# SYSCTL_1.0 register map
Vendor: Texas Instruments
Registers are 32-bit, read-write, no defined reset value unless marked. A register's access mark holds for its fields unless they carry their own. Offsets are as the file gives them; [hi:lo] are bit positions; {n}, {i} and the like mark numbered series; 'fields as' and 'values as' point back to an identical list.

## SYSCTL (part 2 of 2)
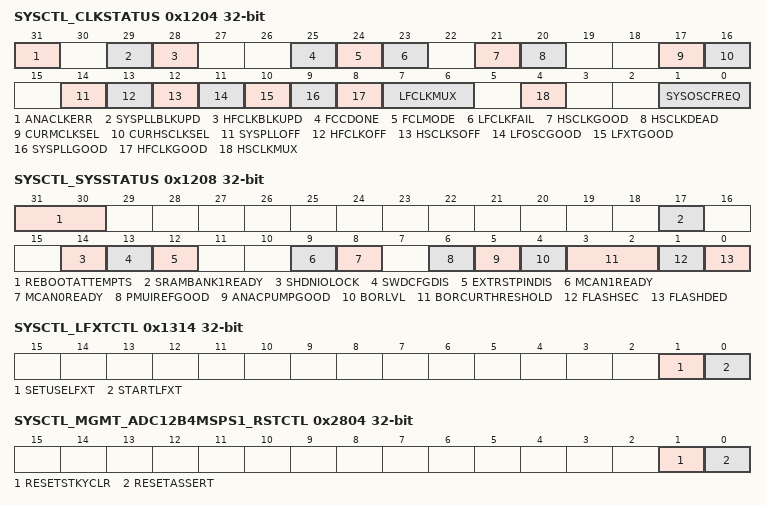
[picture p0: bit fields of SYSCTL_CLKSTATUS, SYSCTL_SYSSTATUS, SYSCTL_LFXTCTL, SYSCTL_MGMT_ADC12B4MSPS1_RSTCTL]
0x1204 SYSCTL_CLKSTATUS ro — Clock module (CKM) status
  [31] ANACLKERR — ANACLKERR is set when the device clock configuration does not support an enabled analog peripheral mode and the analog peripheral may not be functioning as expected.
    0=FALSE (No analog clock errors detected); 1=TRUE (Analog clock error detected)
  [29] SYSPLLBLKUPD — SYSPLLBLKUPD indicates when writes to SYSPLLCFG0/1 and SYSPLLPARAM0/1 are blocked.
    0=FALSE (writes to SYSPLLCFG0/1 and SYSPLLPARAM0/1 are allowed); 1=TRUE (writes to SYSPLLCFG0/1 and SYSPLLPARAM0/1 are blocked)
  [28] HFCLKBLKUPD — HFCLKBLKUPD indicates when writes to the HFCLKCLKCFG register are blocked.
    0=FALSE (Writes to HFCLKCLKCFG are allowed); 1=TRUE (Writes to HFCLKCLKCFG are blocked)
  [25] FCCDONE — FCCDONE indicates when a frequency clock counter capture is complete.
    0=NOTDONE (FCC capture is not done); 1=DONE (FCC capture is done)
  [24] FCLMODE — FCLMODE indicates if the SYSOSC frequency correction loop (FCL) is enabled.
    0=DISABLED (SYSOSC FCL is disabled); 1=ENABLED (SYSOSC FCL is enabled)
  [23] LFCLKFAIL — LFCLKFAIL indicates when the continous LFCLK monitor detects a LFXT or LFCLK_IN clock stuck failure.
    0=FALSE (No LFCLK fault detected); 1=TRUE (LFCLK stuck fault detected)
  [21] HSCLKGOOD — HSCLKGOOD is set by hardware if the selected clock source for HSCLK started successfully.
    0=FALSE (The HSCLK source did not start correctly); 1=TRUE (The HSCLK source started correctly)
  [20] HSCLKDEAD — HSCLKDEAD is set by hardware if the selected source for HSCLK was started but did not start successfully.
    0=FALSE (The HSCLK source was not started or started correctly); 1=TRUE (The HSCLK source did not start correctly)
  [17] CURMCLKSEL — CURMCLKSEL indicates if MCLK is currently sourced from LFCLK.
    0=NOTLFCLK (MCLK is not sourced from LFCLK); 1=LFCLK (MCLK is sourced from LFCLK)
  [16] CURHSCLKSEL — CURHSCLKSEL indicates the current clock source for HSCLK.
    0=SYSPLL (HSCLK is currently sourced from the SYSPLL); 1=HFCLK (HSCLK is currently sourced from the HFCLK)
  [14] SYSPLLOFF — SYSPLLOFF indicates if the SYSPLL is disabled or was dead at startup. When the SYSPLL is started, SYSPLLOFF is cleared by hardware. Following startup of the SYSPLL, if the SYSPLL startup monitor determines that the SYSPLL was not started correctly, SYSPLLOFF is set.
    0=FALSE (SYSPLL started correctly and is enabled); 1=TRUE (SYSPLL is disabled or was dead startup)
  [13] HFCLKOFF — HFCLKOFF indicates if the HFCLK is disabled or was dead at startup. When the HFCLK is started, HFCLKOFF is cleared by hardware. Following startup of the HFCLK, if the HFCLK startup monitor determines that the HFCLK was not started correctly, HFCLKOFF is set.
    0=FALSE (HFCLK started correctly and is enabled); 1=TRUE (HFCLK is disabled or was dead at startup)
  [12] HSCLKSOFF — HSCLKSOFF is set when the high speed clock sources (SYSPLL, HFCLK) are disabled or dead. It is the logical AND of HFCLKOFF and SYSPLLOFF.
    0=FALSE (SYSPLL, HFCLK, or both were started correctly and remain enabled); 1=TRUE (SYSPLL and HFCLK are both either off or dead)
  [11] LFOSCGOOD — LFOSCGOOD indicates when the LFOSC startup has completed and the LFOSC is ready for use.
    0=FALSE (LFOSC is not ready); 1=TRUE (LFOSC is ready)
  [10] LFXTGOOD — LFXTGOOD indicates if the LFXT started correctly. When the LFXT is started, LFXTGOOD is cleared by hardware. After the startup settling time has expired, the LFXT status is tested. If the LFXT started successfully the LFXTGOOD bit is set, else it is left cleared.
    0=FALSE (LFXT did not start correctly); 1=TRUE (LFXT started correctly)
  [9] SYSPLLGOOD — SYSPLLGOOD indicates if the SYSPLL started correctly. When the SYSPLL is started, SYSPLLGOOD is cleared by hardware. After the startup settling time has expired, the SYSPLL status is tested. If the SYSPLL started successfully the SYSPLLGOOD bit is set, else it is left cleared.
    0=FALSE (SYSPLL did not start correctly); 1=TRUE (SYSPLL started correctly)
  [8] HFCLKGOOD — HFCLKGOOD indicates that the HFCLK started correctly. When the HFXT is started or HFCLK_IN is selected as the HFCLK source, this bit will be set by hardware if a valid HFCLK is detected, and cleared if HFCLK is not operating within the expected range.
    0=FALSE (HFCLK did not start correctly); 1=TRUE (HFCLK started correctly)
  [7:6] LFCLKMUX — LFCLKMUX indicates if LFCLK is sourced from the internal LFOSC, the low frequency crystal (LFXT), or the LFCLK_IN digital clock input.
    0=LFOSC (LFCLK is sourced from the internal LFOSC); 1=LFXT (LFCLK is sourced from the LFXT (crystal)); 2=EXLF (LFCLK is sourced from LFCLK_IN (external digital clock input))
  [4] HSCLKMUX — HSCLKMUX indicates if MCLK is currently sourced from the high-speed clock (HSCLK).
    0=SYSOSC (MCLK is not sourced from HSCLK); 1=HSCLK (MCLK is sourced from HSCLK)
  [1:0] SYSOSCFREQ — SYSOSCFREQ indicates the current SYSOSC operating frequency.
    0=SYSOSC32M (SYSOSC is at base frequency (32MHz)); 1=SYSOSC4M (SYSOSC is at low frequency (4MHz)); 2=SYSOSCUSER (SYSOSC is at the user-trimmed frequency (16 or 24MHz)); 3=SYSOSCTURBO (Reserved)
0x1208 SYSCTL_SYSSTATUS ro — System status information
  [31:30] REBOOTATTEMPTS — REBOOTATTEMPTS indicates the number of boot attempts taken before the user application starts.
  [17] SRAMBANK1READY — SRAM BANK1 READY STATE
    0=FALSE (SRAM BANK1 is NOT READY for access); 1=TRUE (SRAM BANK1 is READY for access)
  [14] SHDNIOLOCK — SHDNIOLOCK indicates when IO is locked due to SHUTDOWN
    0=FALSE (IO IS NOT Locked due to SHUTDOWN); 1=TRUE (IO IS Locked due to SHUTDOWN)
  [13] SWDCFGDIS — SWDCFGDIS indicates when user has disabled the use of SWD Port
    0=FALSE (SWD Port Enabled); 1=TRUE (SWD Port Disabled)
  [12] EXTRSTPINDIS — EXTRSTPINDIS indicates when user has disabled the use of external reset pin
    0=FALSE (External Reset Pin Enabled); 1=TRUE (External Reset Pin Disabled)
  [9] MCAN1READY — MCAN1READY indicates when the MCAN1 peripheral is ready.
    0=FALSE (MCAN1 is not ready); 1=TRUE (MCAN1 is ready)
  [8] MCAN0READY — MCAN0READY indicates when the MCAN0 peripheral is ready.
    0=FALSE (MCAN0 is not ready); 1=TRUE (MCAN0 is ready)
  [6] PMUIREFGOOD — PMUIREFGOOD is set by hardware when the PMU current reference is ready.
    0=FALSE (IREF is not ready); 1=TRUE (IREF is ready)
  [5] ANACPUMPGOOD — ANACPUMPGOOD is set by hardware when the VBOOST analog mux charge pump is ready.
    0=FALSE (VBOOST is not ready); 1=TRUE (VBOOST is ready)
  [4] BORLVL — BORLVL indicates if a BOR event occured and the BOR threshold was switched to BOR0 by hardware.
    0=FALSE (No BOR violation occured); 1=TRUE (A BOR violation occured and the BOR threshold was switched to BOR0)
  [3:2] BORCURTHRESHOLD — BORCURTHRESHOLD indicates the active brown-out reset supply monitor configuration.
    0=BORMIN (Default minimum threshold; a BOR0- violation triggers a BOR); 1=BORLEVEL1 (A BOR1- violation generates a BORLVL interrupt); 2=BORLEVEL2 (A BOR2- violation generates a BORLVL interrupt); 3=BORLEVEL3 (A BOR3- violation generates a BORLVL interrupt)
  [1] FLASHSEC — FLASHSEC indicates if a flash ECC single bit error was detected and corrected (SEC).
    0=FALSE (No flash ECC single bit error detected); 1=TRUE (Flash ECC single bit error was detected and corrected)
  [0] FLASHDED — FLASHDED indicates if a flash ECC double bit error was detected (DED).
    0=FALSE (No flash ECC double bit error detected); 1=TRUE (Flash ECC double bit error detected)
0x120C SYSCTL_DEDERRADDR access not given — Memory DED Address
0x1220 SYSCTL_RSTCAUSE ro — Reset cause
  [4:0] ID — ID is a read-to-clear field which indicates the lowest level reset cause since the last read.
    0=NORST (No reset since last read); 1=PORHWFAIL (POR- violation, SHUTDNSTOREx or PMU trim parity fault); 2=POREXNRST (NRST triggered POR (>1s hold)); 3=PORSW (Software triggered POR); 4=BORSUPPLY (BOR0- violation); 5=BORWAKESHUTDN (SHUTDOWN mode exit); 8=BOOTNONPMUPARITY (Non-PMU trim parity fault); 9=BOOTCLKFAIL (Fatal clock failure); 12=BOOTEXNRST (NRST triggered BOOTRST (<1s hold)); 13=BOOTSW (Software triggered BOOTRST); 14=BOOTWWDT0 (WWDT0 violation); 16=SYSBSLEXIT (BSL exit); 17=SYSBSLENTRY (BSL entry); 19=SYSWWDT1 (WWDT1 violation); 20=SYSFLASHECC (Flash uncorrectable ECC error); 21=SYSCPULOCK (CPULOCK violation); 26=SYSDBG (Debug triggered SYSRST); 27=SYSSW (Software triggered SYSRST); 28=CPUDBG (Debug triggered CPURST); 29=CPUSW (Software triggered CPURST)
0x1300 SYSCTL_RESETLEVEL — Reset level for application-triggered reset command
  [2:0] LEVEL — LEVEL is used to specify the type of reset to be issued when RESETCMD is set to generate a software triggered reset.
    0=CPU (Issue a SYSRST (CPU plus peripherals only)); 1=BOOT (Issue a BOOTRST (CPU, peripherals, and boot configuration routine)); 2=BOOTLOADERENTRY (Issue a SYSRST and enter the boot strap loader (BSL)); 3=POR (Issue a power-on reset (POR)); 4=BOOTLOADEREXIT (Issue a SYSRST and exit the boot strap loader (BSL))
0x1304 SYSCTL_RESETCMD — Execute an application-triggered reset command
  [0] GO — Execute the reset specified in RESETLEVEL.LEVEL. Must be written together with the KEY.
    1=TRUE (Issue reset)
0x1308 SYSCTL_BORTHRESHOLD — BOR threshold selection
  [1:0] LEVEL — LEVEL specifies the desired BOR threshold and BOR mode.
    values as SYSCTL_SYSSTATUS.BORCURTHRESHOLD
0x130C SYSCTL_BORCLRCMD — Set the BOR threshold
  [0] GO — GO clears any prior BOR violation status indications and attempts to change the active BOR mode to that specified in the LEVEL field of the BORTHRESHOLD register.
    1=TRUE (Issue clear)
0x1310 SYSCTL_SYSOSCFCLCTL — SYSOSC frequency correction loop (FCL) ROSC enable
  [0] SETUSEFCL — Set SETUSEFCL to enable the frequency correction loop in SYSOSC. Once enabled, this state is locked until the next BOOTRST.
    1=TRUE (Enable the SYSOSC FCL)
0x1314 SYSCTL_LFXTCTL — LFXT and LFCLK control
  [1] SETUSELFXT — Set SETUSELFXT to switch LFCLK to LFXT. Once set, SETUSELFXT remains set until the next BOOTRST.
    0=FALSE; 1=TRUE (Use LFXT as the LFCLK source)
  [0] STARTLFXT — Set STARTLFXT to start the low frequency crystal oscillator (LFXT). Once set, STARTLFXT remains set until the next BOOTRST.
    0=FALSE (LFXT not started); 1=TRUE (Start LFXT)
0x1318 SYSCTL_EXLFCTL — LFCLK_IN and LFCLK control
  [0] SETUSEEXLF — Set SETUSEEXLF to switch LFCLK to the LFCLK_IN digital clock input. Once set, SETUSEEXLF remains set until the next BOOTRST.
    1=TRUE (Use LFCLK_IN as the LFCLK source)
0x131C SYSCTL_SHDNIOREL — SHUTDOWN IO release control
  [0] RELEASE — Set RELEASE to release the IO after a SHUTDOWN mode exit.
    1=TRUE (Release IO)
0x1320 SYSCTL_EXRSTPIN — Disable the reset function of the NRST pin
  [0] DISABLE — Set DISABLE to disable the reset function of the NRST pin. Once set, this configuration is locked until the next POR.
    0=FALSE (Reset function of NRST pin is enabled); 1=TRUE (Reset function of NRST pin is disabled)
0x1324 SYSCTL_SYSSTATUSCLR — Clear sticky bits of SYSSTATUS
  [0] ALLECC — Set ALLECC to clear all ECC related SYSSTATUS indicators.
    1=CLEAR (Clear ECC error state)
0x1328 SYSCTL_SWDCFG — Disable the SWD function on the SWD pins
  [0] DISABLE — Set DISABLE to disable the SWD function on SWD pins, allowing the SWD pins to be used as GPIO.
    1=TRUE (Disable SWD function on SWD pins)
0x132C SYSCTL_FCCCMD — Frequency clock counter start capture
  [0] GO — Set GO to start a capture with the frequency clock counter (FCC).
    1=TRUE
{0x1400+4i} SYSCTL_SHUTDNSTORE{i} (i=0..3) — Shutdown storage memory (byte {i})
  [7:0] DATA — Shutdown storage byte {i}
0x2800 SYSCTL_MGMT_ADC12B4MSPS1_PWREN — IP Enable Register
  [0] ENABLE — IP Enable
    0=Disable; 1=Enable
0x2804 SYSCTL_MGMT_ADC12B4MSPS1_RSTCTL — Power Control Register - Write Only Register, Always Read as 0
  [1] RESETSTKYCLR — Clear the RESET STICKY Bit
    1=Clear
  [0] RESETASSERT — Assert Reset to IP Domain.
    1=Do
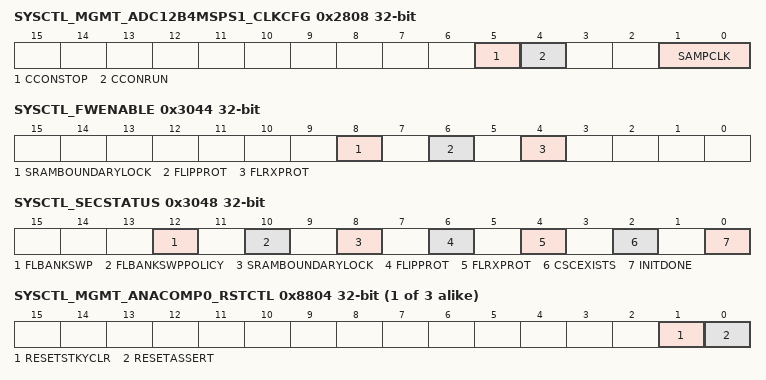
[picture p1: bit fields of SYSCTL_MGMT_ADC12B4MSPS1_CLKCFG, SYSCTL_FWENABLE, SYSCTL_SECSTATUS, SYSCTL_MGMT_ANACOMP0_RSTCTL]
0x2808 SYSCTL_MGMT_ADC12B4MSPS1_CLKCFG — IP Clock Configuration Register
  [5] CCONSTOP — Conversion Clock is ON during STOP Mode
    0=Disable; 1=Enable
  [4] CCONRUN — Conversion Clock is ON during RUN Mode
    0=Disable; 1=Enable
  [1:0] SAMPCLK — Sample Window Clock
    0=ULPCLK; 1=SYSOSC; 2=HFCLK
0x2814 SYSCTL_MGMT_ADC12B4MSPS1_STAT ro — IP State Register - Read Only
  [16] RESETSTKY — IP has been Reset
    0=clear; 1=Set
0x3000 SYSCTL_FWEPROTMAIN access not given — 1 Sector Write-Erase per bit starting at address 0x0 of flash
0x3014 SYSCTL_FWPROTMAINDATA — Read-Write Protection for first 4 Sectors of Data Bank
  [7:0] DATA — 00: Both RW allowed 01: Read Only 10: No Read No Write 11: No Read No Write - Not Used
0x3018 SYSCTL_FRXPROTMAINSTART — Flash RX Protection Start Address
  [21:6] ADDR — Flash RX Protection Start Address 64B granularity
0x301C SYSCTL_FRXPROTMAINEND — Flash RX Protection End Address
  [21:6] ADDR — Flash RX Protection End Address 64B granularity
0x3020 SYSCTL_FIPPROTMAINSTART — Flash IP Protection Start Address
  [21:6] ADDR — Flash IP Protection Start Address 64B granularity
0x3024 SYSCTL_FIPPROTMAINEND — Flash IP Protection End Address
  [21:6] ADDR — Flash IP Protection End Address 64B granularity
0x3038 SYSCTL_FLBANKSWPPOLICY — Flash Bank Swap Policy
  [0] DISABLE — 1: Disables Policy To Allow Flash Bank Swapping
    1=TRUE (Disallow Bank Swap)
0x303C SYSCTL_FLBANKSWP — Flash MAIN bank address swap
  [0] USEUPPER — 1: Use Upper Bank as Logical 0
    0=DISABLE (Normal (default) memory map addressing scheme); 1=ENABLE (Flash upper region address space swapped with lower region)
0x3044 SYSCTL_FWENABLE — Security Firewall Enable Register
  [8] SRAMBOUNDARYLOCK — 1: Blocks Writes from Changing SRAMBOUNDARY MMR
    1=ENABLE (SRAMBOUNDARY MMR Locked)
  [6] FLIPPROT — 1: Flash Read IP ProtectionActive
    1=ENABLE (Turn On Flash IP Protection)
  [4] FLRXPROT — 1: Flash Read Execute Protection Active
    1=ENABLE (Turn On Flash Read-eXecute Protection)
0x3048 SYSCTL_SECSTATUS ro — Security Configuration status
  [12] FLBANKSWP — 1: Upper and Lower Banks have been swapped
  [10] FLBANKSWPPOLICY — 1: Upper and Lower Banks allowed to be swapped
    0=DISABLED; 1=ENABLED
  [8] SRAMBOUNDARYLOCK — 1: SRAM Boundary MMR Locked
    0=DISABLED; 1=ENABLED
  [6] FLIPPROT — 1: Flash IP Protection Active
    0=DISABLED; 1=ENABLED
  [4] FLRXPROT — 1: Flash Read Execute Protection Active
    0=DISABLED; 1=ENABLED
  [2] CSCEXISTS — 1: CSC Exists in the system
    0=NO (System does not have a CSC); 1=YES (System does have a CSC)
  [0] INITDONE — 1: CSC has been completed
    0=NO (INIT is not yet done); 1=YES (INIT is done)
0x3060 SYSCTL_INITDONE — INITCODE PASS
  [0] PASS — INITCODE writes 1 for PASS, left unwritten a timeout will occur if not blocked
    1=TRUE (INITCODE PASS)
{0x8800+0x2000*i} SYSCTL_MGMT_ANACOMP{i}_PWREN (i=0..2) — IP Enable Register
  [0] ENABLE — IP Enable
    0=Disable; 1=Enable
{0x8804+0x2000*i} SYSCTL_MGMT_ANACOMP{i}_RSTCTL (i=0..2) — Power Control Register - Write Only Register, Always Read as 0
  fields as SYSCTL_MGMT_ADC12B4MSPS1_RSTCTL
{0x8808+0x2000*i} SYSCTL_MGMT_ANACOMP{i}_CLKCFG (i=0..2) — IP Clock Configuration Register
  [8] BLOCKASYNC — Async Clock Request is blocked from starting SYSOSC or forcing bus clock to 32MHz
    0=Disable; 1=Enable
{0x8814+0x2000*i} SYSCTL_MGMT_ANACOMP{i}_STAT ro (i=0..2) — IP State Register - Read Only
  [16] RESETSTKY — IP has been Reset
    0=clear; 1=Set
0x18800 SYSCTL_MGMT_DAC12B0_PWREN — IP Enable Register
  [0] ENABLE — IP Enable
    0=Disable; 1=Enable
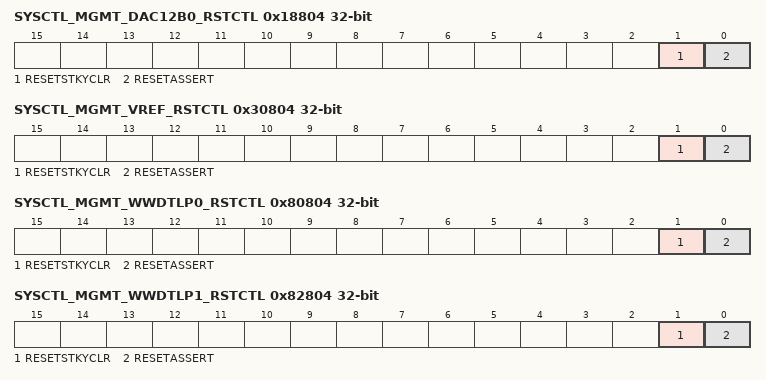
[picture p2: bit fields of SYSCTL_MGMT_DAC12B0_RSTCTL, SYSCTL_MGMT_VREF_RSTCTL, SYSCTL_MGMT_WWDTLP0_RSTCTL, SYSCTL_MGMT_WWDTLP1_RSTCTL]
0x18804 SYSCTL_MGMT_DAC12B0_RSTCTL — Power Control Register - Write Only Register, Always Read as 0
  fields as SYSCTL_MGMT_ADC12B4MSPS1_RSTCTL
0x18814 SYSCTL_MGMT_DAC12B0_STAT ro — IP State Register - Read Only
  [16] RESETSTKY — IP has been Reset
    0=clear; 1=Set
0x30800 SYSCTL_MGMT_VREF_PWREN — IP Enable Register
  [0] ENABLE — IP Enable
    0=Disable; 1=Enable
0x30804 SYSCTL_MGMT_VREF_RSTCTL — Power Control Register - Write Only Register, Always Read as 0
  fields as SYSCTL_MGMT_ADC12B4MSPS1_RSTCTL
0x30814 SYSCTL_MGMT_VREF_STAT ro — IP State Register - Read Only
  [16] RESETSTKY — IP has been Reset
    0=clear; 1=Set
0x80800 SYSCTL_MGMT_WWDTLP0_PWREN — IP Enable Register
  [0] ENABLE — IP Enable
    0=Disable; 1=Enable
0x80804 SYSCTL_MGMT_WWDTLP0_RSTCTL — Power Control Register - Write Only Register, Always Read as 0
  fields as SYSCTL_MGMT_ADC12B4MSPS1_RSTCTL
0x80814 SYSCTL_MGMT_WWDTLP0_STAT ro — IP State Register - Read Only
  [16] RESETSTKY — IP has been Reset
    0=clear; 1=Set
0x82800 SYSCTL_MGMT_WWDTLP1_PWREN — IP Enable Register
  [0] ENABLE — IP Enable
    0=Disable; 1=Enable
0x82804 SYSCTL_MGMT_WWDTLP1_RSTCTL — Power Control Register - Write Only Register, Always Read as 0
  fields as SYSCTL_MGMT_ADC12B4MSPS1_RSTCTL
0x82814 SYSCTL_MGMT_WWDTLP1_STAT ro — IP State Register - Read Only
  [16] RESETSTKY — IP has been Reset
    0=clear; 1=Set
0x84800 SYSCTL_MGMT_GPTIMER16B2CCLP0_PWREN — IP Enable Register
  [0] ENABLE — IP Enable
    0=Disable; 1=Enable
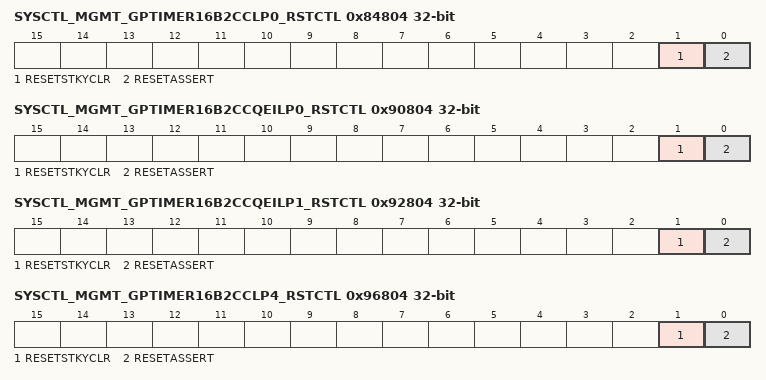
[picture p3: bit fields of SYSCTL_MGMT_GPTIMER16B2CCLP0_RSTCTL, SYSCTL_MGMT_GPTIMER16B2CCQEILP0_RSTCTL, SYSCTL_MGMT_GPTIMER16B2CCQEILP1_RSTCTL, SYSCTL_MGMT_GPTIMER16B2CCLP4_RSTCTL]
0x84804 SYSCTL_MGMT_GPTIMER16B2CCLP0_RSTCTL — Power Control Register - Write Only Register, Always Read as 0
  fields as SYSCTL_MGMT_ADC12B4MSPS1_RSTCTL
0x84814 SYSCTL_MGMT_GPTIMER16B2CCLP0_STAT ro — IP State Register - Read Only
  [16] RESETSTKY — IP has been Reset
    0=clear; 1=Set
0x90800 SYSCTL_MGMT_GPTIMER16B2CCQEILP0_PWREN — IP Enable Register
  [0] ENABLE — IP Enable
    0=Disable; 1=Enable
0x90804 SYSCTL_MGMT_GPTIMER16B2CCQEILP0_RSTCTL — Power Control Register - Write Only Register, Always Read as 0
  fields as SYSCTL_MGMT_ADC12B4MSPS1_RSTCTL
0x90814 SYSCTL_MGMT_GPTIMER16B2CCQEILP0_STAT ro — IP State Register - Read Only
  [16] RESETSTKY — IP has been Reset
    0=clear; 1=Set
0x92800 SYSCTL_MGMT_GPTIMER16B2CCQEILP1_PWREN — IP Enable Register
  [0] ENABLE — IP Enable
    0=Disable; 1=Enable
0x92804 SYSCTL_MGMT_GPTIMER16B2CCQEILP1_RSTCTL — Power Control Register - Write Only Register, Always Read as 0
  fields as SYSCTL_MGMT_ADC12B4MSPS1_RSTCTL
0x92814 SYSCTL_MGMT_GPTIMER16B2CCQEILP1_STAT ro — IP State Register - Read Only
  [16] RESETSTKY — IP has been Reset
    0=clear; 1=Set
0x94808 SYSCTL_MGMT_RTC_CLKCFG — IP Clock Configuration Register
  fields as SYSCTL_MGMT_ANACOMP0_CLKCFG
0x96800 SYSCTL_MGMT_GPTIMER16B2CCLP4_PWREN — IP Enable Register
  [0] ENABLE — IP Enable
    0=Disable; 1=Enable
0x96804 SYSCTL_MGMT_GPTIMER16B2CCLP4_RSTCTL — Power Control Register - Write Only Register, Always Read as 0
  fields as SYSCTL_MGMT_ADC12B4MSPS1_RSTCTL
0x96814 SYSCTL_MGMT_GPTIMER16B2CCLP4_STAT ro — IP State Register - Read Only
  [16] RESETSTKY — IP has been Reset
    0=clear; 1=Set
{0xA0800+0x2000*i} SYSCTL_MGMT_GPIO{i}_PWREN (i=0..2) — IP Enable Register
  [0] ENABLE — IP Enable
    0=Disable; 1=Enable
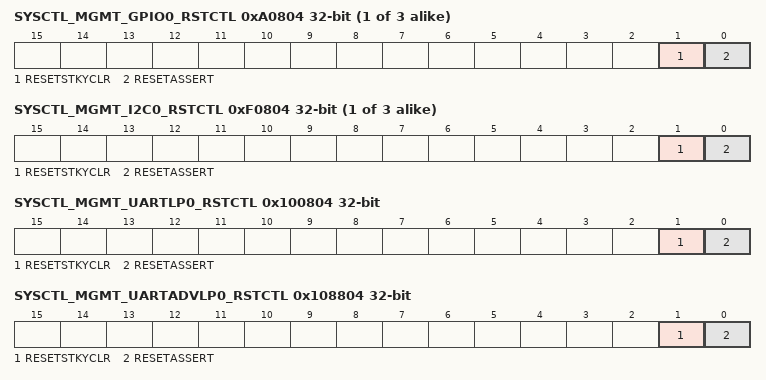
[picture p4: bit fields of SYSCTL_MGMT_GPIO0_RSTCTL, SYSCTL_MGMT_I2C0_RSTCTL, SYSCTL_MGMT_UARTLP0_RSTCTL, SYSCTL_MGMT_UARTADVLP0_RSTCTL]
{0xA0804+0x2000*i} SYSCTL_MGMT_GPIO{i}_RSTCTL (i=0..2) — Power Control Register - Write Only Register, Always Read as 0
  fields as SYSCTL_MGMT_ADC12B4MSPS1_RSTCTL
{0xA0814+0x2000*i} SYSCTL_MGMT_GPIO{i}_STAT ro (i=0..2) — IP State Register - Read Only
  [16] RESETSTKY — IP has been Reset
    0=clear; 1=Set
{0xF0800+0x2000*i} SYSCTL_MGMT_I2C{i}_PWREN (i=0..2) — IP Enable Register
  [0] ENABLE — IP Enable
    0=Disable; 1=Enable
{0xF0804+0x2000*i} SYSCTL_MGMT_I2C{i}_RSTCTL (i=0..2) — Power Control Register - Write Only Register, Always Read as 0
  fields as SYSCTL_MGMT_ADC12B4MSPS1_RSTCTL
{0xF0808+0x2000*i} SYSCTL_MGMT_I2C{i}_CLKCFG (i=0..2) — IP Clock Configuration Register
  fields as SYSCTL_MGMT_ANACOMP0_CLKCFG
{0xF0814+0x2000*i} SYSCTL_MGMT_I2C{i}_STAT ro (i=0..2) — IP State Register - Read Only
  [16] RESETSTKY — IP has been Reset
    0=clear; 1=Set
0x100800 SYSCTL_MGMT_UARTLP0_PWREN — IP Enable Register
  [0] ENABLE — IP Enable
    0=Disable; 1=Enable
0x100804 SYSCTL_MGMT_UARTLP0_RSTCTL — Power Control Register - Write Only Register, Always Read as 0
  fields as SYSCTL_MGMT_ADC12B4MSPS1_RSTCTL
0x100808 SYSCTL_MGMT_UARTLP0_CLKCFG — IP Clock Configuration Register
  fields as SYSCTL_MGMT_ANACOMP0_CLKCFG
0x100814 SYSCTL_MGMT_UARTLP0_STAT ro — IP State Register - Read Only
  [16] RESETSTKY — IP has been Reset
    0=clear; 1=Set
0x108800 SYSCTL_MGMT_UARTADVLP0_PWREN — IP Enable Register
  [0] ENABLE — IP Enable
    0=Disable; 1=Enable
0x108804 SYSCTL_MGMT_UARTADVLP0_RSTCTL — Power Control Register - Write Only Register, Always Read as 0
  fields as SYSCTL_MGMT_ADC12B4MSPS1_RSTCTL
0x108808 SYSCTL_MGMT_UARTADVLP0_CLKCFG — IP Clock Configuration Register
  fields as SYSCTL_MGMT_ANACOMP0_CLKCFG
0x108814 SYSCTL_MGMT_UARTADVLP0_STAT ro — IP State Register - Read Only
  [16] RESETSTKY — IP has been Reset
    0=clear; 1=Set
0x10A800 SYSCTL_MGMT_UARTADVLP1_PWREN — IP Enable Register
  [0] ENABLE — IP Enable
    0=Disable; 1=Enable
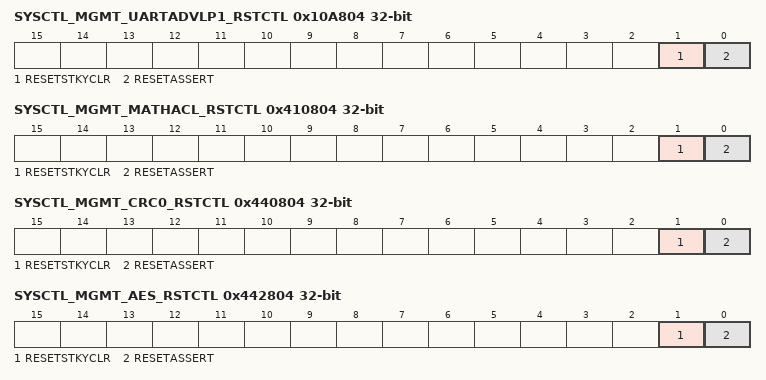
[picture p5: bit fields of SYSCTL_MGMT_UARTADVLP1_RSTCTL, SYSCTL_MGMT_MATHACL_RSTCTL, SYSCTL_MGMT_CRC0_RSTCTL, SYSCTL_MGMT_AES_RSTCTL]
0x10A804 SYSCTL_MGMT_UARTADVLP1_RSTCTL — Power Control Register - Write Only Register, Always Read as 0
  fields as SYSCTL_MGMT_ADC12B4MSPS1_RSTCTL
0x10A808 SYSCTL_MGMT_UARTADVLP1_CLKCFG — IP Clock Configuration Register
  fields as SYSCTL_MGMT_ANACOMP0_CLKCFG
0x10A814 SYSCTL_MGMT_UARTADVLP1_STAT ro — IP State Register - Read Only
  [16] RESETSTKY — IP has been Reset
    0=clear; 1=Set
0x410800 SYSCTL_MGMT_MATHACL_PWREN — IP Enable Register
  [0] ENABLE — IP Enable
    0=Disable; 1=Enable
0x410804 SYSCTL_MGMT_MATHACL_RSTCTL — Power Control Register - Write Only Register, Always Read as 0
  fields as SYSCTL_MGMT_ADC12B4MSPS1_RSTCTL
0x410814 SYSCTL_MGMT_MATHACL_STAT ro — IP State Register - Read Only
  [16] RESETSTKY — IP has been Reset
    0=clear; 1=Set
0x440800 SYSCTL_MGMT_CRC0_PWREN — IP Enable Register
  [0] ENABLE — IP Enable
    0=Disable; 1=Enable
0x440804 SYSCTL_MGMT_CRC0_RSTCTL — Power Control Register - Write Only Register, Always Read as 0
  fields as SYSCTL_MGMT_ADC12B4MSPS1_RSTCTL
0x440814 SYSCTL_MGMT_CRC0_STAT ro — IP State Register - Read Only
  [16] RESETSTKY — IP has been Reset
    0=clear; 1=Set
0x442800 SYSCTL_MGMT_AES_PWREN — IP Enable Register
  [0] ENABLE — IP Enable
    0=Disable; 1=Enable
0x442804 SYSCTL_MGMT_AES_RSTCTL — Power Control Register - Write Only Register, Always Read as 0
  fields as SYSCTL_MGMT_ADC12B4MSPS1_RSTCTL
0x442814 SYSCTL_MGMT_AES_STAT ro — IP State Register - Read Only
  [16] RESETSTKY — IP has been Reset
    0=clear; 1=Set
0x444800 SYSCTL_MGMT_TRNG_PWREN — IP Enable Register
  [0] ENABLE — IP Enable
    0=Disable; 1=Enable
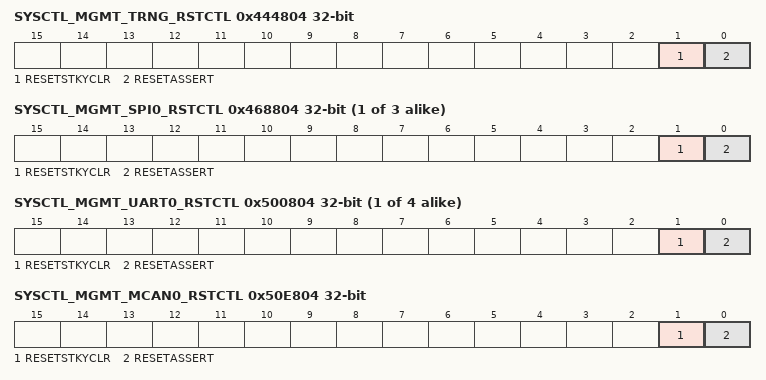
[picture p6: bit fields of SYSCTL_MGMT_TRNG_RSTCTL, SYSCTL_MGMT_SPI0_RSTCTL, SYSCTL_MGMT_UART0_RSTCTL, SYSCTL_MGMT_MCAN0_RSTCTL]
0x444804 SYSCTL_MGMT_TRNG_RSTCTL — Power Control Register - Write Only Register, Always Read as 0
  fields as SYSCTL_MGMT_ADC12B4MSPS1_RSTCTL
0x444814 SYSCTL_MGMT_TRNG_STAT ro — IP State Register - Read Only
  [16] RESETSTKY — IP has been Reset
    0=clear; 1=Set
{0x468800+0x2000*i} SYSCTL_MGMT_SPI{i}_PWREN (i=0..2) — IP Enable Register
  [0] ENABLE — IP Enable
    0=Disable; 1=Enable
{0x468804+0x2000*i} SYSCTL_MGMT_SPI{i}_RSTCTL (i=0..2) — Power Control Register - Write Only Register, Always Read as 0
  fields as SYSCTL_MGMT_ADC12B4MSPS1_RSTCTL
{0x468808+0x2000*i} SYSCTL_MGMT_SPI{i}_CLKCFG (i=0..2) — IP Clock Configuration Register
  fields as SYSCTL_MGMT_ANACOMP0_CLKCFG
{0x468814+0x2000*i} SYSCTL_MGMT_SPI{i}_STAT ro (i=0..2) — IP State Register - Read Only
  [16] RESETSTKY — IP has been Reset
    0=clear; 1=Set
{0x500800+0x2000*i} SYSCTL_MGMT_UART{i}_PWREN (i=0..3) — IP Enable Register
  [0] ENABLE — IP Enable
    0=Disable; 1=Enable
{0x500804+0x2000*i} SYSCTL_MGMT_UART{i}_RSTCTL (i=0..3) — Power Control Register - Write Only Register, Always Read as 0
  fields as SYSCTL_MGMT_ADC12B4MSPS1_RSTCTL
{0x500808+0x2000*i} SYSCTL_MGMT_UART{i}_CLKCFG (i=0..3) — IP Clock Configuration Register
  fields as SYSCTL_MGMT_ANACOMP0_CLKCFG
{0x500814+0x2000*i} SYSCTL_MGMT_UART{i}_STAT ro (i=0..3) — IP State Register - Read Only
  [16] RESETSTKY — IP has been Reset
    0=clear; 1=Set
0x50E800 SYSCTL_MGMT_MCAN0_PWREN — IP Enable Register
  [0] ENABLE — IP Enable
    0=Disable; 1=Enable
0x50E804 SYSCTL_MGMT_MCAN0_RSTCTL — Power Control Register - Write Only Register, Always Read as 0
  fields as SYSCTL_MGMT_ADC12B4MSPS1_RSTCTL
0x50E814 SYSCTL_MGMT_MCAN0_STAT ro — IP State Register - Read Only
  [16] RESETSTKY — IP has been Reset
    0=clear; 1=Set
0x516800 SYSCTL_MGMT_MCAN1_PWREN — IP Enable Register
  [0] ENABLE — IP Enable
    0=Disable; 1=Enable
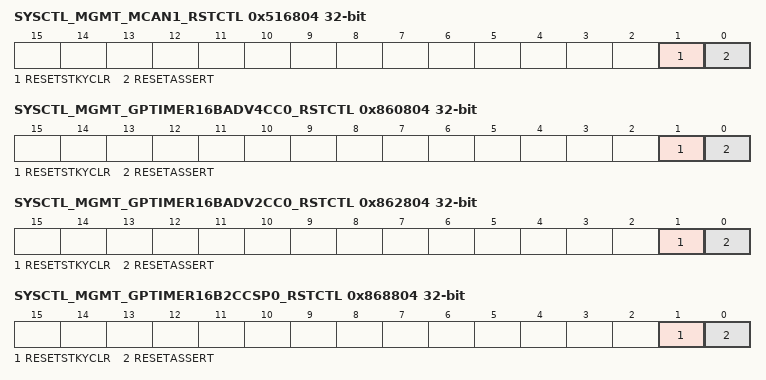
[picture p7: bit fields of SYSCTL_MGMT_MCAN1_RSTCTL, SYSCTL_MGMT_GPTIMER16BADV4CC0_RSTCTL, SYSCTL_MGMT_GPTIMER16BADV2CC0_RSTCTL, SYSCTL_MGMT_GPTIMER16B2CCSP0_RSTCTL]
0x516804 SYSCTL_MGMT_MCAN1_RSTCTL — Power Control Register - Write Only Register, Always Read as 0
  fields as SYSCTL_MGMT_ADC12B4MSPS1_RSTCTL
0x516814 SYSCTL_MGMT_MCAN1_STAT ro — IP State Register - Read Only
  [16] RESETSTKY — IP has been Reset
    0=clear; 1=Set
0x860800 SYSCTL_MGMT_GPTIMER16BADV4CC0_PWREN — IP Enable Register
  [0] ENABLE — IP Enable
    0=Disable; 1=Enable
0x860804 SYSCTL_MGMT_GPTIMER16BADV4CC0_RSTCTL — Power Control Register - Write Only Register, Always Read as 0
  fields as SYSCTL_MGMT_ADC12B4MSPS1_RSTCTL
0x860814 SYSCTL_MGMT_GPTIMER16BADV4CC0_STAT ro — IP State Register - Read Only
  [16] RESETSTKY — IP has been Reset
    0=clear; 1=Set
0x862800 SYSCTL_MGMT_GPTIMER16BADV2CC0_PWREN — IP Enable Register
  [0] ENABLE — IP Enable
    0=Disable; 1=Enable
0x862804 SYSCTL_MGMT_GPTIMER16BADV2CC0_RSTCTL — Power Control Register - Write Only Register, Always Read as 0
  fields as SYSCTL_MGMT_ADC12B4MSPS1_RSTCTL
0x862814 SYSCTL_MGMT_GPTIMER16BADV2CC0_STAT ro — IP State Register - Read Only
  [16] RESETSTKY — IP has been Reset
    0=clear; 1=Set
0x868800 SYSCTL_MGMT_GPTIMER16B2CCSP0_PWREN — IP Enable Register
  [0] ENABLE — IP Enable
    0=Disable; 1=Enable
0x868804 SYSCTL_MGMT_GPTIMER16B2CCSP0_RSTCTL — Power Control Register - Write Only Register, Always Read as 0
  fields as SYSCTL_MGMT_ADC12B4MSPS1_RSTCTL
0x868814 SYSCTL_MGMT_GPTIMER16B2CCSP0_STAT ro — IP State Register - Read Only
  [16] RESETSTKY — IP has been Reset
    0=clear; 1=Set
0x86A800 SYSCTL_MGMT_GPTIMER16B2CCSP1_PWREN — IP Enable Register
  [0] ENABLE — IP Enable
    0=Disable; 1=Enable
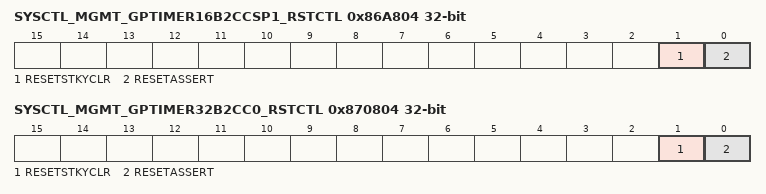
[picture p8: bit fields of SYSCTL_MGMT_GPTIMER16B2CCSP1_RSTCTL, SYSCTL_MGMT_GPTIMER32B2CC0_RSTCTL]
0x86A804 SYSCTL_MGMT_GPTIMER16B2CCSP1_RSTCTL — Power Control Register - Write Only Register, Always Read as 0
  fields as SYSCTL_MGMT_ADC12B4MSPS1_RSTCTL
0x86A814 SYSCTL_MGMT_GPTIMER16B2CCSP1_STAT ro — IP State Register - Read Only
  [16] RESETSTKY — IP has been Reset
    0=clear; 1=Set
0x870800 SYSCTL_MGMT_GPTIMER32B2CC0_PWREN — IP Enable Register
  [0] ENABLE — IP Enable
    0=Disable; 1=Enable
0x870804 SYSCTL_MGMT_GPTIMER32B2CC0_RSTCTL — Power Control Register - Write Only Register, Always Read as 0
  fields as SYSCTL_MGMT_ADC12B4MSPS1_RSTCTL
0x870814 SYSCTL_MGMT_GPTIMER32B2CC0_STAT ro — IP State Register - Read Only
  [16] RESETSTKY — IP has been Reset
    0=clear; 1=Set
